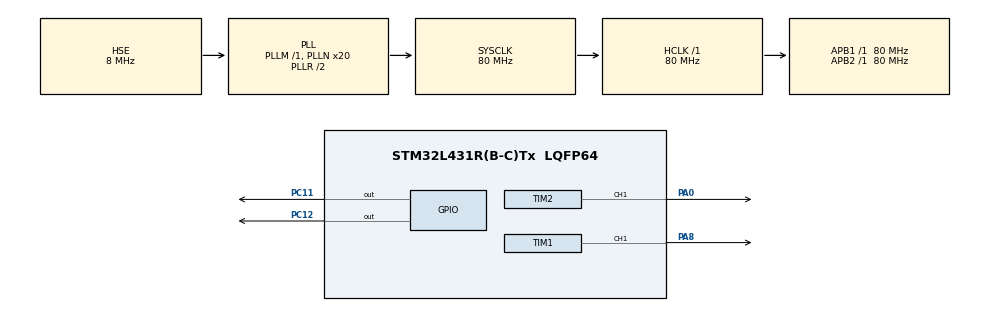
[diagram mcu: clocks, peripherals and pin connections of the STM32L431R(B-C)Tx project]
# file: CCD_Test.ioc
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Mcu.Family=STM32L4
Mcu.Name=STM32L431R(B-C)Tx
Mcu.Package=LQFP64
NVIC.PriorityGroup=NVIC_PRIORITYGROUP_4
NVIC.TIM1_CC_IRQn=true\:1\:0\:true\:false\:true\:true\:true\:true
NVIC.TIM2_IRQn=true\:0\:0\:false\:false\:true\:true\:true\:true
PA0.Signal=S_TIM2_CH1
PA13\ (JTMS-SWDIO).Mode=Serial_Wire
PA13\ (JTMS-SWDIO).Signal=SYS_JTMS-SWDIO
PA14\ (JTCK-SWCLK).Mode=Serial_Wire
PA14\ (JTCK-SWCLK).Signal=SYS_JTCK-SWCLK
PA8.Signal=S_TIM1_CH1
PC11.Signal=GPIO_Output
PC12.GPIO_Speed=GPIO_SPEED_FREQ_HIGH
PC12.Signal=GPIO_Output
PH0-OSC_IN\ (PH0).Mode=HSE-External-Oscillator
PH0-OSC_IN\ (PH0).Signal=RCC_OSC_IN
PH1-OSC_OUT\ (PH1).Mode=HSE-External-Oscillator
PH1-OSC_OUT\ (PH1).Signal=RCC_OSC_OUT
ProjectManager.HeapSize=0x200
ProjectManager.StackSize=0x400
ProjectManager.TargetToolchain=STM32CubeIDE
RCC.ADCFreq_Value=32000000
RCC.AHBFreq_Value=80000000
RCC.APB1Freq_Value=80000000
RCC.APB1TimFreq_Value=80000000
RCC.APB2Freq_Value=80000000
RCC.APB2TimFreq_Value=80000000
RCC.CortexFreq_Value=80000000
RCC.HCLKFreq_Value=80000000
RCC.HSE_VALUE=8000000
RCC.HSI48_VALUE=48000000
RCC.HSI_VALUE=16000000
RCC.LSE_VALUE=32768
RCC.MSI_VALUE=4000000
RCC.PLLN=20
RCC.PLLSourceVirtual=RCC_PLLSOURCE_HSE
RCC.SYSCLKFreq_VALUE=80000000
RCC.SYSCLKSource=RCC_SYSCLKSOURCE_PLLCLK
RCC.VCOOutputFreq_Value=160000000
SH.S_TIM1_CH1.0=TIM1_CH1,PWM Generation1 CH1
SH.S_TIM2_CH1.0=TIM2_CH1,PWM Generation1 CH1
TIM1.Channel-PWM\ Generation1\ CH1=TIM_CHANNEL_1
TIM1.Period=39
TIM1.Pulse-PWM\ Generation1\ CH1=19
TIM2.Channel-Output\ Compare4\ No\ Output=TIM_CHANNEL_4
TIM2.Channel-PWM\ Generation1\ CH1=TIM_CHANNEL_1
TIM2.OCMode_4=TIM_OCMODE_ACTIVE
TIM2.OCPolarity_1=TIM_OCPOLARITY_LOW
TIM2.Period=248159
TIM2.Prescaler=0
TIM2.Pulse-PWM\ Generation1\ CH1=799
TIM2.TIM_MasterOutputTrigger=TIM_TRGO_OC4REF
TIM2.TIM_MasterSlaveMode=TIM_MASTERSLAVEMODE_DISABLE
VP_TIM1_VS_ClockSourceITR.Mode=TriggerSource_ITR1
VP_TIM1_VS_ControllerModeTrigger.Mode=Trigger Mode
VP_TIM2_VS_no_output4.Mode=Output Compare4 No Output
board=custom

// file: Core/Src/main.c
/* USER CODE BEGIN Header */
/**
  ******************************************************************************
  * @file           : main.c
  * @brief          : Main program body
  ******************************************************************************
  * @attention
  *
  * Copyright (c) 2024 STMicroelectronics.
  * All rights reserved.
  *
  * This software is licensed under terms that can be found in the LICENSE file
  * in the root directory of this software component.
  * If no LICENSE file comes with this software, it is provided AS-IS.
  *
  ******************************************************************************
  */

/**
 * TIM1 for SH, tim1 channel 1 generate pwm, tim1 channel 2 output compare no output (Trigger to tim15)
 * TIM2 for ICG, tim2 channel 1 generate pwm, tim2 channel 2 output compare no output (Trigger to tim1)
 * TIM15 for Phi M, tim15 channel 1 generate pwm
 *
 */

/* USER CODE END Header */
#include "main.h"

/* USER CODE BEGIN Includes */
#include "ccd.h"
/* USER CODE END Includes */

TIM_HandleTypeDef htim1;
TIM_HandleTypeDef htim2;

/* USER CODE BEGIN PV */
struct ccd tcd1103;
/* USER CODE END PV */

void SystemClock_Config(void);
static void MX_GPIO_Init(void);
static void MX_TIM2_Init(void);
static void MX_TIM1_Init(void);

/* USER CODE BEGIN 0 */
//void HAL_TIM_PWM_PulseFinishedHalfCpltCallback(TIM_HandleTypeDef *htim)
//void HAL_TIM_PWM_PulseFinishedCallback(TIM_HandleTypeDef *htim)
//{
//  if (htim == &htim15) {
//	  GPIOC->ODR ^= GPIO_PIN_12;
//  }
//}
/* USER CODE END 0 */

int main(void)
{

  /* USER CODE BEGIN 1 */
	uint32_t i_time = 0;
  /* USER CODE END 1 */

  /* MCU Configuration--------------------------------------------------------*/

  /* Reset of all peripherals, Initializes the Flash interface and the Systick. */
  HAL_Init();

  /* Configure the system clock */
  SystemClock_Config();

  /* Initialize all configured peripherals */
  MX_GPIO_Init();
  MX_TIM2_Init();
  MX_TIM1_Init();
  /* USER CODE BEGIN 2 */
  ccd_init(&tcd1103, &htim2, &htim1, GPIOC, GPIO_PIN_12);
  set_integration_time(&tcd1103, 5000);

  i_time = get_integration_time_us(&tcd1103);
  get_spectrum(&tcd1103);
  UNUSED(i_time);
  /* USER CODE END 2 */

  /* Infinite loop */
  while (1)
  {

  }
}

void SystemClock_Config(void)
{
  RCC_OscInitTypeDef RCC_OscInitStruct = {0};
  RCC_ClkInitTypeDef RCC_ClkInitStruct = {0};

  /** Configure the main internal regulator output voltage
  */
  if (HAL_PWREx_ControlVoltageScaling(PWR_REGULATOR_VOLTAGE_SCALE1) != HAL_OK)
  {
    Error_Handler();
  }

  /** Initializes the RCC Oscillators according to the specified parameters
  * in the RCC_OscInitTypeDef structure.
  */
  RCC_OscInitStruct.OscillatorType = RCC_OSCILLATORTYPE_HSE;
  RCC_OscInitStruct.HSEState = RCC_HSE_ON;
  RCC_OscInitStruct.PLL.PLLState = RCC_PLL_ON;
  RCC_OscInitStruct.PLL.PLLSource = RCC_PLLSOURCE_HSE;
  RCC_OscInitStruct.PLL.PLLM = 1;
  RCC_OscInitStruct.PLL.PLLN = 20;
  RCC_OscInitStruct.PLL.PLLP = RCC_PLLP_DIV7;
  RCC_OscInitStruct.PLL.PLLQ = RCC_PLLQ_DIV2;
  RCC_OscInitStruct.PLL.PLLR = RCC_PLLR_DIV2;
  if (HAL_RCC_OscConfig(&RCC_OscInitStruct) != HAL_OK)
  {
    Error_Handler();
  }

  /** Initializes the CPU, AHB and APB buses clocks
  */
  RCC_ClkInitStruct.ClockType = RCC_CLOCKTYPE_HCLK|RCC_CLOCKTYPE_SYSCLK
                              |RCC_CLOCKTYPE_PCLK1|RCC_CLOCKTYPE_PCLK2;
  RCC_ClkInitStruct.SYSCLKSource = RCC_SYSCLKSOURCE_PLLCLK;
  RCC_ClkInitStruct.AHBCLKDivider = RCC_SYSCLK_DIV1;
  RCC_ClkInitStruct.APB1CLKDivider = RCC_HCLK_DIV1;
  RCC_ClkInitStruct.APB2CLKDivider = RCC_HCLK_DIV1;

  if (HAL_RCC_ClockConfig(&RCC_ClkInitStruct, FLASH_LATENCY_4) != HAL_OK)
  {
    Error_Handler();
  }
}

static void MX_TIM1_Init(void)
{

  TIM_SlaveConfigTypeDef sSlaveConfig = {0};
  TIM_MasterConfigTypeDef sMasterConfig = {0};
  TIM_OC_InitTypeDef sConfigOC = {0};
  TIM_BreakDeadTimeConfigTypeDef sBreakDeadTimeConfig = {0};

  htim1.Instance = TIM1;
  htim1.Init.Prescaler = 0;
  htim1.Init.CounterMode = TIM_COUNTERMODE_UP;
  htim1.Init.Period = 39;
  htim1.Init.ClockDivision = TIM_CLOCKDIVISION_DIV1;
  htim1.Init.RepetitionCounter = 0;
  htim1.Init.AutoReloadPreload = TIM_AUTORELOAD_PRELOAD_DISABLE;
  if (HAL_TIM_Base_Init(&htim1) != HAL_OK)
  {
    Error_Handler();
  }
  if (HAL_TIM_PWM_Init(&htim1) != HAL_OK)
  {
    Error_Handler();
  }
  sSlaveConfig.SlaveMode = TIM_SLAVEMODE_TRIGGER;
  sSlaveConfig.InputTrigger = TIM_TS_ITR1;
  if (HAL_TIM_SlaveConfigSynchro(&htim1, &sSlaveConfig) != HAL_OK)
  {
    Error_Handler();
  }
  sMasterConfig.MasterOutputTrigger = TIM_TRGO_RESET;
  sMasterConfig.MasterOutputTrigger2 = TIM_TRGO2_RESET;
  sMasterConfig.MasterSlaveMode = TIM_MASTERSLAVEMODE_DISABLE;
  if (HAL_TIMEx_MasterConfigSynchronization(&htim1, &sMasterConfig) != HAL_OK)
  {
    Error_Handler();
  }
  sConfigOC.OCMode = TIM_OCMODE_PWM1;
  sConfigOC.Pulse = 19;
  sConfigOC.OCPolarity = TIM_OCPOLARITY_HIGH;
  sConfigOC.OCNPolarity = TIM_OCNPOLARITY_HIGH;
  sConfigOC.OCFastMode = TIM_OCFAST_DISABLE;
  sConfigOC.OCIdleState = TIM_OCIDLESTATE_RESET;
  sConfigOC.OCNIdleState = TIM_OCNIDLESTATE_RESET;
  if (HAL_TIM_PWM_ConfigChannel(&htim1, &sConfigOC, TIM_CHANNEL_1) != HAL_OK)
  {
    Error_Handler();
  }
  sBreakDeadTimeConfig.OffStateRunMode = TIM_OSSR_DISABLE;
  sBreakDeadTimeConfig.OffStateIDLEMode = TIM_OSSI_DISABLE;
  sBreakDeadTimeConfig.LockLevel = TIM_LOCKLEVEL_OFF;
  sBreakDeadTimeConfig.DeadTime = 0;
  sBreakDeadTimeConfig.BreakState = TIM_BREAK_DISABLE;
  sBreakDeadTimeConfig.BreakPolarity = TIM_BREAKPOLARITY_HIGH;
  sBreakDeadTimeConfig.BreakFilter = 0;
  sBreakDeadTimeConfig.Break2State = TIM_BREAK2_DISABLE;
  sBreakDeadTimeConfig.Break2Polarity = TIM_BREAK2POLARITY_HIGH;
  sBreakDeadTimeConfig.Break2Filter = 0;
  sBreakDeadTimeConfig.AutomaticOutput = TIM_AUTOMATICOUTPUT_DISABLE;
  if (HAL_TIMEx_ConfigBreakDeadTime(&htim1, &sBreakDeadTimeConfig) != HAL_OK)
  {
    Error_Handler();
  }
  HAL_TIM_MspPostInit(&htim1);

}

static void MX_TIM2_Init(void)
{

  TIM_MasterConfigTypeDef sMasterConfig = {0};
  TIM_OC_InitTypeDef sConfigOC = {0};

  htim2.Instance = TIM2;
  htim2.Init.Prescaler = 0;
  htim2.Init.CounterMode = TIM_COUNTERMODE_UP;
  htim2.Init.Period = 248159;
  htim2.Init.ClockDivision = TIM_CLOCKDIVISION_DIV1;
  htim2.Init.AutoReloadPreload = TIM_AUTORELOAD_PRELOAD_DISABLE;
  if (HAL_TIM_PWM_Init(&htim2) != HAL_OK)
  {
    Error_Handler();
  }
  if (HAL_TIM_OC_Init(&htim2) != HAL_OK)
  {
    Error_Handler();
  }
  sMasterConfig.MasterOutputTrigger = TIM_TRGO_OC4REF;
  sMasterConfig.MasterSlaveMode = TIM_MASTERSLAVEMODE_DISABLE;
  if (HAL_TIMEx_MasterConfigSynchronization(&htim2, &sMasterConfig) != HAL_OK)
  {
    Error_Handler();
  }
  sConfigOC.OCMode = TIM_OCMODE_PWM1;
  sConfigOC.Pulse = 799;
  sConfigOC.OCPolarity = TIM_OCPOLARITY_LOW;
  sConfigOC.OCFastMode = TIM_OCFAST_DISABLE;
  if (HAL_TIM_PWM_ConfigChannel(&htim2, &sConfigOC, TIM_CHANNEL_1) != HAL_OK)
  {
    Error_Handler();
  }
  sConfigOC.OCMode = TIM_OCMODE_ACTIVE;
  sConfigOC.Pulse = 0;
  sConfigOC.OCPolarity = TIM_OCPOLARITY_HIGH;
  if (HAL_TIM_OC_ConfigChannel(&htim2, &sConfigOC, TIM_CHANNEL_4) != HAL_OK)
  {
    Error_Handler();
  }
  HAL_TIM_MspPostInit(&htim2);

}

static void MX_GPIO_Init(void)
{
  GPIO_InitTypeDef GPIO_InitStruct = {0};

  /* GPIO Ports Clock Enable */
  __HAL_RCC_GPIOH_CLK_ENABLE();
  __HAL_RCC_GPIOA_CLK_ENABLE();
  __HAL_RCC_GPIOC_CLK_ENABLE();

  /*Configure GPIO pin Output Level */
  HAL_GPIO_WritePin(GPIOC, GPIO_PIN_11|GPIO_PIN_12, GPIO_PIN_RESET);

  /*Configure GPIO pin : PC11 */
  GPIO_InitStruct.Pin = GPIO_PIN_11;
  GPIO_InitStruct.Mode = GPIO_MODE_OUTPUT_PP;
  GPIO_InitStruct.Pull = GPIO_NOPULL;
  GPIO_InitStruct.Speed = GPIO_SPEED_FREQ_LOW;
  HAL_GPIO_Init(GPIOC, &GPIO_InitStruct);

  /*Configure GPIO pin : PC12 */
  GPIO_InitStruct.Pin = GPIO_PIN_12;
  GPIO_InitStruct.Mode = GPIO_MODE_OUTPUT_PP;
  GPIO_InitStruct.Pull = GPIO_NOPULL;
  GPIO_InitStruct.Speed = GPIO_SPEED_FREQ_HIGH;
  HAL_GPIO_Init(GPIOC, &GPIO_InitStruct);

}

void Error_Handler(void)
{
  __disable_irq();
  while (1)
  {
  }
}
